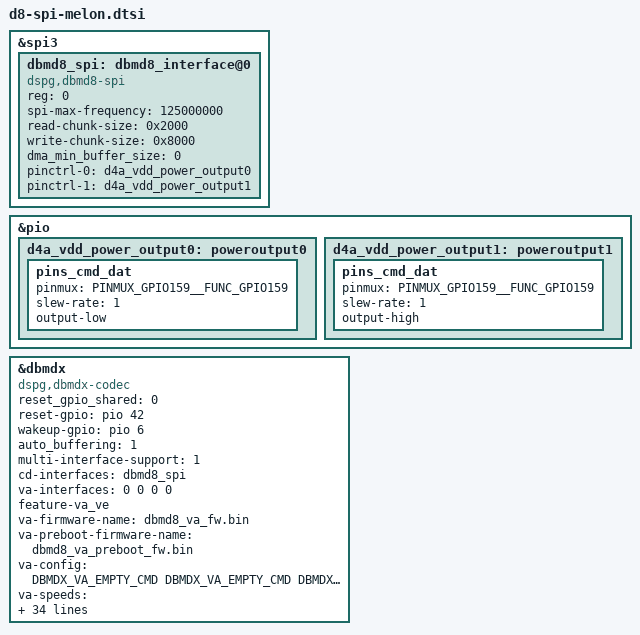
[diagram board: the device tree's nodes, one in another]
#include <dt-bindings/sound/dbmdx-va-regmap.h>

#define DBMDX_QED_SUPPORTED		0
/* Model Support */
#define DBMDX_OKG_WWE_SUPPORT		0
#define DBMDX_SENSORY_WWE_SUPPORT	1
#define DBMDX_AMAZON_WWE_SUPPORT	0

#define DBMDX_LARGE_AMODEL_SUPPORT	1

/* Chip Type */
#define DBMDX_VA_CHIP_TYPE_D4P		1

/* Master Clock */
#define DBMDX_MCLOCK_VA_32KHZ		1
#define DBMDX_MCLOCK_VA_12MHZ		0
#define DBMDX_MCLOCK_VA_24MHZ		0

/* Wakeup support */
#define DBMDX_WAKEUP_VA_ENABLED		1
#define DBMDX_LOW_POWER_MODE_ENABLED	1

#define DBMDX_USE_ANALOG_MICS		1

&spi3 {
	 #address-cells = <1>;
   	 #size-cells = <0>;
	 status = "okay";
         dbmd8_spi:dbmd8_interface@0  {
                 compatible = "dspg,dbmd8-spi";
                 reg = <0>;
		 spi-max-frequency = <125000000>;
		 read-chunk-size  = <0x2000> ;
		 write-chunk-size = <0x8000> ;
		 dma_min_buffer_size = <0>;
		 /*vdd-gpio = <&pio 159 0>;*/
		 pinctrl-names = "state_power_output0","state_power_output1";
		 pinctrl-0 = <&d4a_vdd_power_output0>;
		 pinctrl-1 = <&d4a_vdd_power_output1>;
         };
};

&pio {
	d4a_vdd_power_output0: poweroutput0 {
		pins_cmd_dat {
			pinmux = <PINMUX_GPIO159__FUNC_GPIO159>;
			slew-rate = <1>;
			output-low;
		};
	};
	d4a_vdd_power_output1: poweroutput1 {
		pins_cmd_dat {
			pinmux = <PINMUX_GPIO159__FUNC_GPIO159>;
			slew-rate = <1>;
			output-high;
		};
	};
};

&dbmdx {
		status = "okay";
		compatible = "dspg,dbmdx-codec";
		reset_gpio_shared = <0>;
		reset-gpio = <&pio 42 0>;
		/*sv-gpio = <&pio 23 0>;*/
		wakeup-gpio = <&pio 6 0>;
		auto_buffering = <1>;
		multi-interface-support = <1>;
		cd-interfaces = < &dbmd8_spi >;
		va-interfaces = <0 0 0 0>;
		feature-va_ve; /* enable VA_VE */
		va-firmware-name = "dbmd8_va_fw.bin";
		va-preboot-firmware-name = "dbmd8_va_preboot_fw.bin";
		va-config =	<DBMDX_VA_EMPTY_CMD
				DBMDX_VA_EMPTY_CMD
				DBMDX_VA_EMPTY_CMD
				(DBMDX_REGN_HOST_INTERFACE_SUPPORT |
					DBMDX_REGV_SPI_D2_TDM1_D4_GPIO_4_5_6_7)
				(DBMDX_REGN_MASTER_CLOCK_FREQUENCY |
#if DBMDX_MCLOCK_VA_24MHZ
					DBMDX_REGV_MCLK_24576000Hz)
#elif DBMDX_MCLOCK_VA_12MHZ
					DBMDX_REGV_MCLK_12288000Hz)
#else /* 32KHZ */
					DBMDX_REGV_MCLK_32768Hz)
#endif
				(DBMDX_REGN_AUDIO_BUFFER_SIZE |
#if DBMDX_VA_CHIP_TYPE_D4P
					DBMDX_REGV_AUDIO_BUFFER_3_SEC)
#else /* D4 */
					DBMDX_REGV_AUDIO_BUFFER_1_5_SEC)
#endif
				(DBMDX_REGN_GENERAL_CONFIG_1 |
					DBMDX_REGV_DSP_CLK_GEN_PLL |
					DBMDX_REGV_SPLIT_MIC_BUFFER |
					DBMDX_REGV_MAX_NUMBER_OF_MIC_IS_4)
				(DBMDX_REGN_MEMORY_CONFIG |
					DBMDX_REGV_AMODEL_0_LOC_DTCM |
					DBMDX_REGV_AUDIO_BUF_LOC_AHB_USING_MEM_ALLOCATION |
#if DBMDX_VA_CHIP_TYPE_D4P
					DBMDX_REGV_AMODEL_1_LOC_DTCM |
					DBMDX_REGV_AMODEL_4_LOC_DTCM |
					DBMDX_REGV_AHB_ON_SIZE_192KW_32KW_CACHE_D8 |
					DBMDX_REGV_DTCM_SIZE_D4_D6_96_KW_D8_192KW)
#else
					DBMDX_REGV_AMODEL_4_LOC_AHB |
					DBMDX_REGV_AHB_ON_SIZE_128KW_16KW_CACHE |
					DBMDX_REGV_DTCM_SIZE_D4_D6_96_KW_D8_128KW)
#endif
				(DBMDX_REGN_GENERAL_CONFIG_2 |
					DBMDX_REGV_MIC_SAMPLE_RATE_16K |
					DBMDX_REGV_DDF_SAMPLE_WIDTH_16_BIT |
					DBMDX_REGV_FW_VAD_TYPE_NO_VAD)
#if DBMDX_OKG_WWE_SUPPORT == 0
				(DBMDX_REGN_BUFFERING_NORMAL_AMPLITUDE |
					DBMDX_REGV_NORMALIZE_TO_MINUS_6dB)
#endif
#if DBMDX_USE_ANALOG_MICS
				(DBMDX_REGN_MICROPHONE_ANALOG_GAIN |
					DBMDX_REGV_SAR_GAIN_31_8_DB)
				(DBMDX_REGN_MICROPHONE_ANALOG_GAIN |
					DBMDX_REGV_SD_GAIN_32_DB)
#endif

				(DBMDX_REGN_GPIO_CONFIG |
					DBMDX_REGV_SET_SEC_GPIO |
					DBMDX_REGV_SEC_MODEL_DET_GPIO_NUM_20 |
					DBMDX_REGV_SET_PRI_GPIO |
					DBMDX_REGV_PRI_MODEL_DET_GPIO_NUM_20 )
				(DBMDX_REGN_HPF_ENABLE_DISABLE |
					0x0010 |
					DBMDX_REGV_IIR_HPF_EN |
					DBMDX_REGV_DC_REMOVE_COARSE_EN)
				(DBMDX_REGN_DSP_CLOCK_CONFIG |
#if DBMDX_MCLOCK_VA_24MHZ
					DBMDX_REGV_PLL_STEP_3 |
#elif DBMDX_MCLOCK_VA_12MHZ
					DBMDX_REGV_PLL_STEP_6 |
#else /* 32Khz */
					DBMDX_REGV_PLL_STEP_7 |
#endif
					DBMDX_REGV_TL3_DIV_1 |
					DBMDX_REGV_APB_DIV_1 |
					DBMDX_REGV_AHB_DIV_1)

				(DBMDX_VA_MSLEEP | 0x0040)
				(DBMDX_REGN_UART_SPEED |
					DBMDX_REGV_UART_BAUD_RATE_3_Mhz)
				DBMDX_VA_EMPTY_CMD
				DBMDX_VA_EMPTY_CMD
				DBMDX_VA_EMPTY_CMD>;

		va-speeds = <0x0000 460800  0 1000000
			     0x0000 2000000 0 3000000
			     0x0000 3000000 0 5000000>;
		va-mic-config = <0x5076 0xa061 0x0008>;
		va_ve-mic-config = <0x5076 0xa061 0xa093 0x0000>;
		va-mic-mode = <0>;
		master-clk-rate = <32768>;
		default_va_clock = <98304000>;
		/* constant-clk-rate = <32768>; */
		auto_detection = <1>;
		firmware_id = <0xdbd8>;
		wakeup_disabled = <0>;
		use_gpio_for_wakeup = <1>; /* Use wakeup gpio */
		send_wakeup_seq = <0>; /* Send wakup seq */
		wakeup_set_value = <0>;

		uart_low_speed_enabled = <1>;
		detection_buffer_channels = <0>;
		pcm_streaming_mode = <1>;
		boot_options = <0x220>; /* Verify chip id */
		send_uevent_on_detection = <1>;
		send_uevent_after_buffering = <1>;
		detection_after_buffering = <1>;
		change_clock_src_options = <0x4003>;
		va_backlog_length = <502>;
		qed_enabled = <0>;
		low_power_mode_disabled = <0>;
		hw_revision = <0>;
		project_sub_type = <1>;	/* VT ONLY - MELON */
		buffering_timeout = <5>;
		default-streaming-usecase-name = "uc_melon_ga_2mic_aec_48k";
		alsa_streaming_options = <0x8>;
		asrp_tx_out_gain = <0x2cfc>; /* gain=15: (int)((10^(gain/20))*2048) */
		asrp_vcpf_out_gain = <0x2cfc>; /* gain=15: (int)((10^(gain/20))*2048) */
		asrp_rx_out_gain = <0x2cfc>; /* gain=15: (int)((10^(gain/20))*2048) */
		asrp_delay = <1>;
		amodel_options = <1>;
};

